# STM32H7B0 register map
File version: 2.3
CPU: CM7 r0p1, little endian, MPU, FPU, 4 interrupt priority bits
Registers are 32-bit, read-write, reset 0x0 unless marked. A register's access mark holds for its fields unless they carry their own. Offsets are from the block's base; [hi:lo] are bit positions; {n}, {i} and the like mark numbered series.

## COMP1
Base 0x58003800
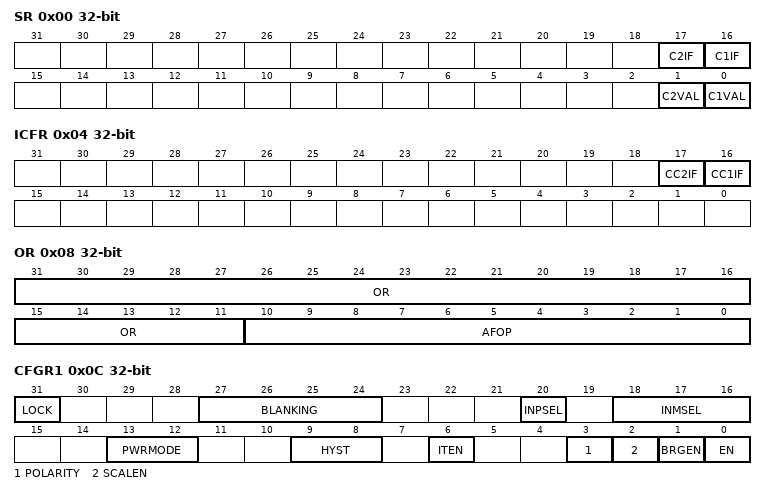
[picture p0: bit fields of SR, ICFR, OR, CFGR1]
0x00 SR ro — Comparator status register
  [17] C2IF — COMP channel 2 Interrupt Flag
  [16] C1IF — COMP channel 1 Interrupt Flag
  [1] C2VAL — COMP channel 2 output status bit
  [0] C1VAL — COMP channel 1 output status bit
0x04 ICFR wo — Comparator interrupt clear flag register
  [17] CC2IF — Clear COMP channel 2 Interrupt Flag
  [16] CC1IF — Clear COMP channel 1 Interrupt Flag
0x08 OR — Comparator option register
  [31:11] OR — Option Register
  [10:0] AFOP — Selection of source for alternate function of output ports
0x0C CFGR1 — Comparator configuration register 1
  [31] LOCK — Lock bit
  [27:24] BLANKING — COMP channel 1 blanking source selection bits
  [20] INPSEL — COMP channel 1 non-inverting input selection bit
  [18:16] INMSEL — COMP channel 1 inverting input selection field
  [13:12] PWRMODE — Power Mode of the COMP channel 1
  [9:8] HYST — COMP channel 1 hysteresis selection bits
  [6] ITEN — COMP channel 1 interrupt enable
  [3] POLARITY — COMP channel 1 polarity selection bit
  [2] SCALEN — Voltage scaler enable bit
  [1] BRGEN — Scaler bridge enable
  [0] EN — COMP channel 1 enable bit
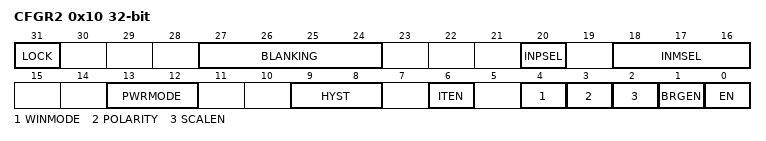
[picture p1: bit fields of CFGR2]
0x10 CFGR2 — Comparator configuration register 2
  [31] LOCK — Lock bit
  [27:24] BLANKING — COMP channel 1 blanking source selection bits
  [20] INPSEL — COMP channel 1 non-inverting input selection bit
  [18:16] INMSEL — COMP channel 1 inverting input selection field
  [13:12] PWRMODE — Power Mode of the COMP channel 1
  [9:8] HYST — COMP channel 1 hysteresis selection bits
  [6] ITEN — COMP channel 1 interrupt enable
  [4] WINMODE — Window comparator mode selection bit
  [3] POLARITY — COMP channel 1 polarity selection bit
  [2] SCALEN — Voltage scaler enable bit
  [1] BRGEN — Scaler bridge enable
  [0] EN — COMP channel 1 enable bit

## HSEM
Base 0x48020800
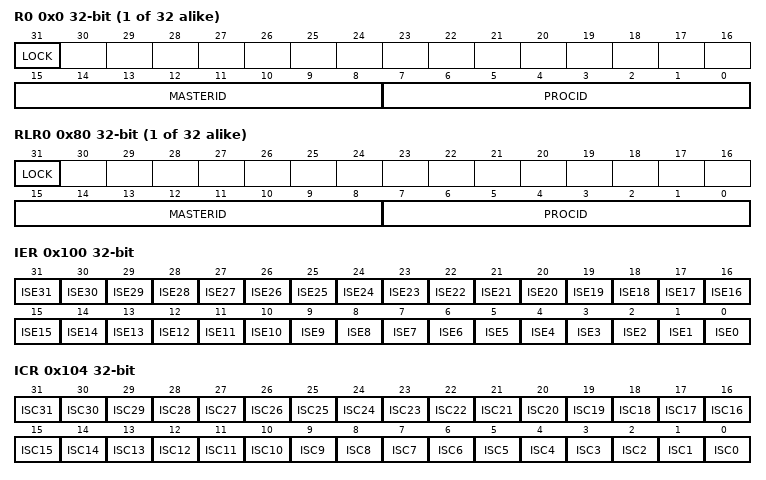
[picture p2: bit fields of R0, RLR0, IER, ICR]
{0x0+4i} R{i} (i=0..31) — HSEM register HSEM_R{i}
  [31] LOCK — Lock indication
    on read: 0=Free (Semaphore is free); 1=Locked (Semaphore is locked) | on write: 0=Free semaphore; 1=TryLock (Try to lock semaphore)
  [15:8] MASTERID range 0..15 — Semaphore MasterID
  [7:0] PROCID — Semaphore ProcessID
{0x80+4i} RLR{i} (i=0..31) ro — Semaphore {i} read lock register
  [31] LOCK — Lock indication
    0=Free (Semaphore is free); 1=Locked (Semaphore is locked)
  [15:8] MASTERID range 0..15 — Semaphore MasterID
  [7:0] PROCID — Semaphore ProcessID
0x100 IER — HSEM Interrupt enable register
  [n] ISE{n} (n=0..31) — Interrupt semaphore {n} enable bit
    0=Disabled (Interrupt generation disabled); 1=Enabled (Interrupt generation enabled)
0x104 ICR — HSEM Interrupt clear register
  [n] ISC{n} (n=0..31) — Interrupt semaphore {n} clear bit
    on read: 0=NoEffect (Always reads 0) | on write: 0=NoEffect (Interrupt semaphore x status ISFx and masked status MISFx not affected); 1=Clear (Interrupt semaphore x status ISFx and masked status MISFx cleared)
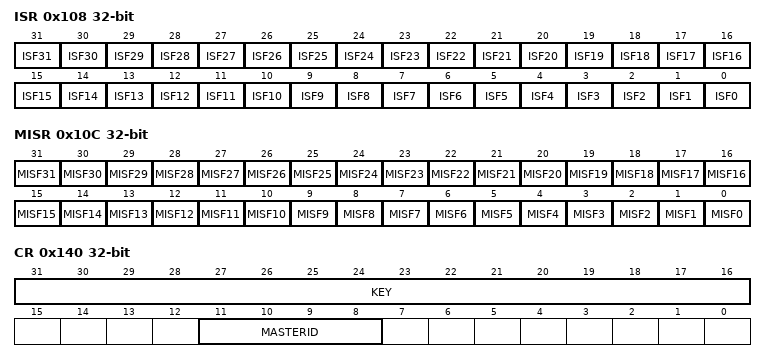
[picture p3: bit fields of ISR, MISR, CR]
0x108 ISR ro — HSEM Interrupt status register
  [n] ISF{n} (n=0..31) — Interrupt semaphore {n} status bit before enable (mask)
    0=NotPending (No interrupt pending); 1=Pending (Interrupt pending)
0x10C MISR ro — HSEM Masked interrupt status register
  [n] MISF{n} (n=0..31) — Masked interrupt semaphore {n} status bit after enable (mask)
    0=NotPending (No interrupt pending after masking); 1=Pending (Interrupt pending after masking)
0x140 CR — HSEM Clear register
  [31:16] KEY — Semaphore clear Key
  [11:8] MASTERID — MasterID of semaphores to be cleared
0x144 KEYR — HSEM Interrupt clear register
  [31:16] KEY — Semaphore Clear Key

## VREFBUF
Base 0x58003C00
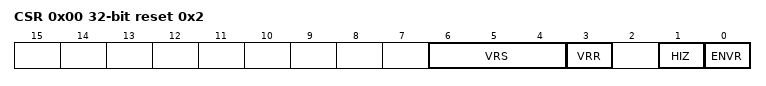
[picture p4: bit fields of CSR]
0x00 CSR access per field reset 0x2 — VREFBUF control and status register
  [6:4] VRS rw — Voltage reference scale These bits select the value generated by the voltage reference buffer. Other: Reserved
  [3] VRR ro — Voltage reference buffer ready
  [1] HIZ rw — High impedance mode This bit controls the analog switch to connect or not the VREF+ pin. Refer to Table196: VREF buffer modes for the mode descriptions depending on ENVR bit configuration.
  [0] ENVR rw — Voltage reference buffer mode enable This bit is used to enable the voltage reference buffer mode.
0x04 CCR — VREFBUF calibration control register
  [5:0] TRIM — Trimming code These bits are automatically initialized after reset with the trimming value stored in the Flash memory during the production test. Writing into these bits allows to tune the internal reference buffer voltage.
